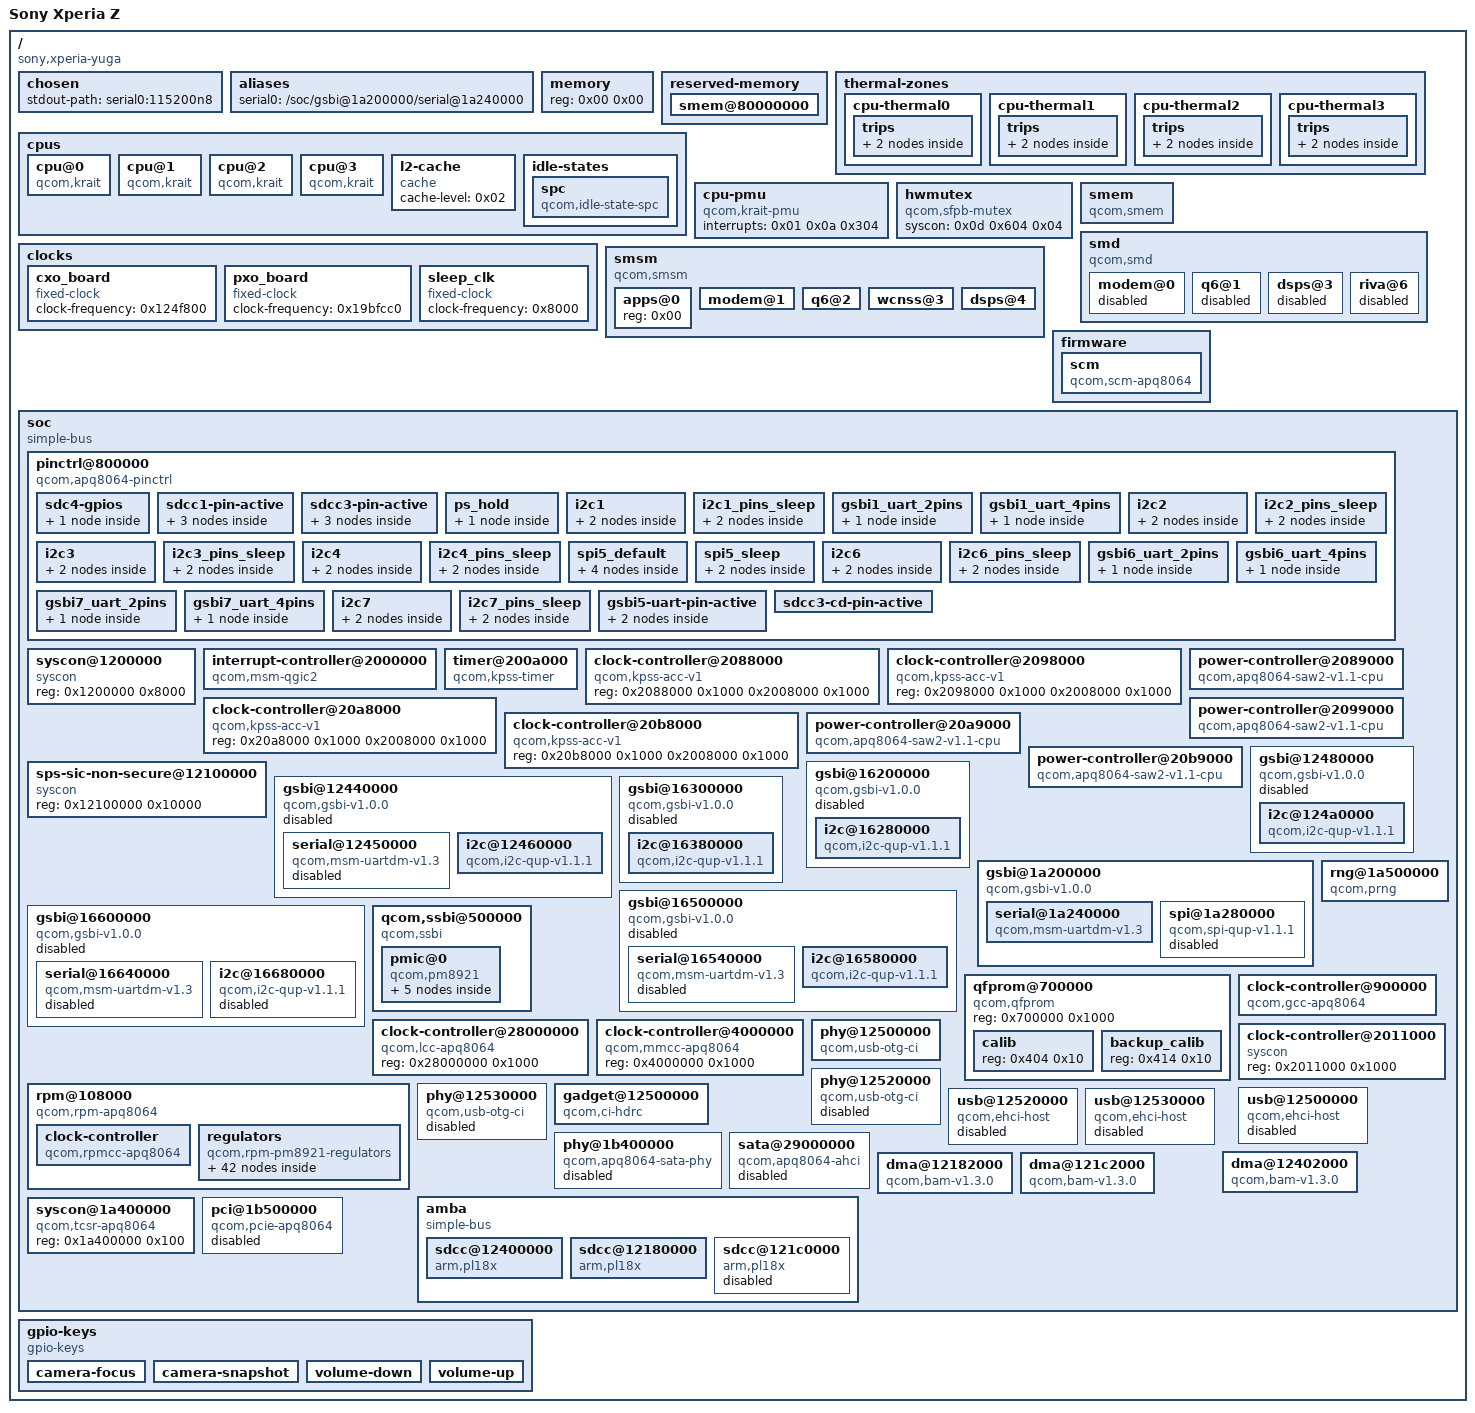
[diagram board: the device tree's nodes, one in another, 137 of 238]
/dts-v1/;

/ {
	#address-cells = <0x01>;
	#size-cells = <0x01>;
	model = "Sony Xperia Z";
	compatible = "sony,xperia-yuga\0qcom,apq8064";
	interrupt-parent = <0x01>;

	chosen {
		stdout-path = "serial0:115200n8";
	};

	aliases {
		serial0 = "/soc/gsbi@1a200000/serial@1a240000";
	};

	memory {
		device_type = "memory";
		reg = <0x00 0x00>;
	};

	reserved-memory {
		#address-cells = <0x01>;
		#size-cells = <0x01>;
		ranges;

		smem@80000000 {
			reg = <0x80000000 0x200000>;
			no-map;
			phandle = <0x0e>;
		};
	};

	cpus {
		#address-cells = <0x01>;
		#size-cells = <0x00>;

		cpu@0 {
			compatible = "qcom,krait";
			enable-method = "qcom,kpss-acc-v1";
			device_type = "cpu";
			reg = <0x00>;
			next-level-cache = <0x02>;
			qcom,acc = <0x03>;
			qcom,saw = <0x04>;
			cpu-idle-states = <0x05>;
		};

		cpu@1 {
			compatible = "qcom,krait";
			enable-method = "qcom,kpss-acc-v1";
			device_type = "cpu";
			reg = <0x01>;
			next-level-cache = <0x02>;
			qcom,acc = <0x06>;
			qcom,saw = <0x07>;
			cpu-idle-states = <0x05>;
		};

		cpu@2 {
			compatible = "qcom,krait";
			enable-method = "qcom,kpss-acc-v1";
			device_type = "cpu";
			reg = <0x02>;
			next-level-cache = <0x02>;
			qcom,acc = <0x08>;
			qcom,saw = <0x09>;
			cpu-idle-states = <0x05>;
		};

		cpu@3 {
			compatible = "qcom,krait";
			enable-method = "qcom,kpss-acc-v1";
			device_type = "cpu";
			reg = <0x03>;
			next-level-cache = <0x02>;
			qcom,acc = <0x0a>;
			qcom,saw = <0x0b>;
			cpu-idle-states = <0x05>;
		};

		l2-cache {
			compatible = "cache";
			cache-level = <0x02>;
			phandle = <0x02>;
		};

		idle-states {

			spc {
				compatible = "qcom,idle-state-spc\0arm,idle-state";
				entry-latency-us = <0x190>;
				exit-latency-us = <0x384>;
				min-residency-us = <0xbb8>;
				phandle = <0x05>;
			};
		};
	};

	thermal-zones {

		cpu-thermal0 {
			polling-delay-passive = <0xfa>;
			polling-delay = <0x3e8>;
			thermal-sensors = <0x0c 0x07>;
			coefficients = <0x4af 0x00>;

			trips {

				trip0 {
					temperature = <0x124f8>;
					hysteresis = <0x7d0>;
					type = "passive";
					phandle = <0x3c>;
				};

				trip1 {
					temperature = <0x1adb0>;
					hysteresis = <0x7d0>;
					type = "critical";
					phandle = <0x3d>;
				};
			};
		};

		cpu-thermal1 {
			polling-delay-passive = <0xfa>;
			polling-delay = <0x3e8>;
			thermal-sensors = <0x0c 0x08>;
			coefficients = <0x46c 0x00>;

			trips {

				trip0 {
					temperature = <0x124f8>;
					hysteresis = <0x7d0>;
					type = "passive";
					phandle = <0x3e>;
				};

				trip1 {
					temperature = <0x1adb0>;
					hysteresis = <0x7d0>;
					type = "critical";
					phandle = <0x3f>;
				};
			};
		};

		cpu-thermal2 {
			polling-delay-passive = <0xfa>;
			polling-delay = <0x3e8>;
			thermal-sensors = <0x0c 0x09>;
			coefficients = <0x4af 0x00>;

			trips {

				trip0 {
					temperature = <0x124f8>;
					hysteresis = <0x7d0>;
					type = "passive";
					phandle = <0x40>;
				};

				trip1 {
					temperature = <0x1adb0>;
					hysteresis = <0x7d0>;
					type = "critical";
					phandle = <0x41>;
				};
			};
		};

		cpu-thermal3 {
			polling-delay-passive = <0xfa>;
			polling-delay = <0x3e8>;
			thermal-sensors = <0x0c 0x0a>;
			coefficients = <0x46c 0x00>;

			trips {

				trip0 {
					temperature = <0x124f8>;
					hysteresis = <0x7d0>;
					type = "passive";
					phandle = <0x42>;
				};

				trip1 {
					temperature = <0x1adb0>;
					hysteresis = <0x7d0>;
					type = "critical";
					phandle = <0x43>;
				};
			};
		};
	};

	cpu-pmu {
		compatible = "qcom,krait-pmu";
		interrupts = <0x01 0x0a 0x304>;
	};

	clocks {

		cxo_board {
			compatible = "fixed-clock";
			#clock-cells = <0x00>;
			clock-frequency = <0x124f800>;
		};

		pxo_board {
			compatible = "fixed-clock";
			#clock-cells = <0x00>;
			clock-frequency = <0x19bfcc0>;
		};

		sleep_clk {
			compatible = "fixed-clock";
			#clock-cells = <0x00>;
			clock-frequency = <0x8000>;
		};
	};

	hwmutex {
		compatible = "qcom,sfpb-mutex";
		syscon = <0x0d 0x604 0x04>;
		#hwlock-cells = <0x01>;
		phandle = <0x0f>;
	};

	smem {
		compatible = "qcom,smem";
		memory-region = <0x0e>;
		hwlocks = <0x0f 0x03>;
	};

	smd {
		compatible = "qcom,smd";

		modem@0 {
			interrupts = <0x00 0x25 0x01>;
			qcom,ipc = <0x10 0x08 0x03>;
			qcom,smd-edge = <0x00>;
			status = "disabled";
		};

		q6@1 {
			interrupts = <0x00 0x5a 0x01>;
			qcom,ipc = <0x10 0x08 0x0f>;
			qcom,smd-edge = <0x01>;
			status = "disabled";
		};

		dsps@3 {
			interrupts = <0x00 0x8a 0x01>;
			qcom,ipc = <0x11 0x4080 0x00>;
			qcom,smd-edge = <0x03>;
			status = "disabled";
		};

		riva@6 {
			interrupts = <0x00 0xc6 0x01>;
			qcom,ipc = <0x10 0x08 0x19>;
			qcom,smd-edge = <0x06>;
			status = "disabled";
		};
	};

	smsm {
		compatible = "qcom,smsm";
		#address-cells = <0x01>;
		#size-cells = <0x00>;
		qcom,ipc-1 = <0x10 0x08 0x04>;
		qcom,ipc-2 = <0x10 0x08 0x0e>;
		qcom,ipc-3 = <0x10 0x08 0x17>;
		qcom,ipc-4 = <0x11 0x4094 0x00>;

		apps@0 {
			reg = <0x00>;
			#qcom,smem-state-cells = <0x01>;
			phandle = <0x44>;
		};

		modem@1 {
			reg = <0x01>;
			interrupts = <0x00 0x26 0x01>;
			interrupt-controller;
			#interrupt-cells = <0x02>;
			phandle = <0x45>;
		};

		q6@2 {
			reg = <0x02>;
			interrupts = <0x00 0x59 0x01>;
			interrupt-controller;
			#interrupt-cells = <0x02>;
			phandle = <0x46>;
		};

		wcnss@3 {
			reg = <0x03>;
			interrupts = <0x00 0xcc 0x01>;
			interrupt-controller;
			#interrupt-cells = <0x02>;
			phandle = <0x47>;
		};

		dsps@4 {
			reg = <0x04>;
			interrupts = <0x00 0x89 0x01>;
			interrupt-controller;
			#interrupt-cells = <0x02>;
			phandle = <0x48>;
		};
	};

	firmware {

		scm {
			compatible = "qcom,scm-apq8064";
		};
	};

	soc {
		#address-cells = <0x01>;
		#size-cells = <0x01>;
		ranges;
		compatible = "simple-bus";
		phandle = <0x49>;

		pinctrl@800000 {
			compatible = "qcom,apq8064-pinctrl";
			reg = <0x800000 0x4000>;
			gpio-controller;
			#gpio-cells = <0x02>;
			interrupt-controller;
			#interrupt-cells = <0x02>;
			interrupts = <0x00 0x10 0x04>;
			pinctrl-names = "default";
			pinctrl-0 = <0x12>;
			phandle = <0x23>;

			sdc4-gpios {
				phandle = <0x39>;

				pios {
					pins = "gpio63\0gpio64\0gpio65\0gpio66\0gpio67\0gpio68";
					function = "sdc4";
				};
			};

			sdcc1-pin-active {
				phandle = <0x32>;

				clk {
					pins = "sdc1_clk";
					drive-strengh = <0x10>;
					bias-disable;
				};

				cmd {
					pins = "sdc1_cmd";
					drive-strengh = <0x0a>;
					bias-pull-up;
				};

				data {
					pins = "sdc1_data";
					drive-strengh = <0x0a>;
					bias-pull-up;
				};
			};

			sdcc3-pin-active {
				phandle = <0x36>;

				clk {
					pins = "sdc3_clk";
					drive-strengh = <0x08>;
					bias-disable;
				};

				cmd {
					pins = "sdc3_cmd";
					drive-strengh = <0x08>;
					bias-pull-up;
				};

				data {
					pins = "sdc3_data";
					drive-strengh = <0x08>;
					bias-pull-up;
				};
			};

			ps_hold {
				phandle = <0x12>;

				mux {
					pins = "gpio78";
					function = "ps_hold";
				};
			};

			i2c1 {
				phandle = <0x14>;

				mux {
					pins = "gpio20\0gpio21";
					function = "gsbi1";
				};

				pinconf {
					pins = "gpio20\0gpio21";
					drive-strength = <0x10>;
					bias-disable;
				};
			};

			i2c1_pins_sleep {
				phandle = <0x15>;

				mux {
					pins = "gpio20\0gpio21";
					function = "gpio";
				};

				pinconf {
					pins = "gpio20\0gpio21";
					drive-strength = <0x02>;
					bias-disable = <0x00>;
				};
			};

			gsbi1_uart_2pins {
				phandle = <0x4a>;

				mux {
					pins = "gpio18\0gpio19";
					function = "gsbi1";
				};
			};

			gsbi1_uart_4pins {
				phandle = <0x4b>;

				mux {
					pins = "gpio18\0gpio19\0gpio20\0gpio21";
					function = "gsbi1";
				};
			};

			i2c2 {
				phandle = <0x16>;

				mux {
					pins = "gpio24\0gpio25";
					function = "gsbi2";
				};

				pinconf {
					pins = "gpio24\0gpio25";
					drive-strength = <0x10>;
					bias-disable;
				};
			};

			i2c2_pins_sleep {
				phandle = <0x17>;

				mux {
					pins = "gpio24\0gpio25";
					function = "gpio";
				};

				pinconf {
					pins = "gpio24\0gpio25";
					drive-strength = <0x02>;
					bias-disable = <0x00>;
				};
			};

			i2c3 {
				phandle = <0x18>;

				mux {
					pins = "gpio8\0gpio9";
					function = "gsbi3";
				};

				pinconf {
					pins = "gpio8\0gpio9";
					drive-strength = <0x10>;
					bias-disable;
				};
			};

			i2c3_pins_sleep {
				phandle = <0x19>;

				mux {
					pins = "gpio8\0gpio9";
					function = "gpio";
				};

				pinconf {
					pins = "gpio8\0gpio9";
					drive-strength = <0x02>;
					bias-disable = <0x00>;
				};
			};

			i2c4 {
				phandle = <0x1a>;

				mux {
					pins = "gpio12\0gpio13";
					function = "gsbi4";
				};

				pinconf {
					pins = "gpio12\0gpio13";
					drive-strength = <0x10>;
					bias-disable;
				};
			};

			i2c4_pins_sleep {
				phandle = <0x1b>;

				mux {
					pins = "gpio12\0gpio13";
					function = "gpio";
				};

				pinconf {
					pins = "gpio12\0gpio13";
					drive-strength = <0x02>;
					bias-disable = <0x00>;
				};
			};

			spi5_default {
				phandle = <0x1d>;

				pinmux {
					pins = "gpio51\0gpio52\0gpio54";
					function = "gsbi5";
				};

				pinmux_cs {
					function = "gpio";
					pins = "gpio53";
				};

				pinconf {
					pins = "gpio51\0gpio52\0gpio54";
					drive-strength = <0x10>;
					bias-disable;
				};

				pinconf_cs {
					pins = "gpio53";
					drive-strength = <0x10>;
					bias-disable;
					output-high;
				};
			};

			spi5_sleep {
				phandle = <0x1e>;

				pinmux {
					function = "gpio";
					pins = "gpio51\0gpio52\0gpio53\0gpio54";
				};

				pinconf {
					pins = "gpio51\0gpio52\0gpio53\0gpio54";
					drive-strength = <0x02>;
					bias-pull-down;
				};
			};

			i2c6 {
				phandle = <0x1f>;

				mux {
					pins = "gpio16\0gpio17";
					function = "gsbi6";
				};

				pinconf {
					pins = "gpio16\0gpio17";
					drive-strength = <0x10>;
					bias-disable;
				};
			};

			i2c6_pins_sleep {
				phandle = <0x20>;

				mux {
					pins = "gpio16\0gpio17";
					function = "gpio";
				};

				pinconf {
					pins = "gpio16\0gpio17";
					drive-strength = <0x02>;
					bias-disable = <0x00>;
				};
			};

			gsbi6_uart_2pins {
				phandle = <0x4c>;

				mux {
					pins = "gpio14\0gpio15";
					function = "gsbi6";
				};
			};

			gsbi6_uart_4pins {
				phandle = <0x4d>;

				mux {
					pins = "gpio14\0gpio15\0gpio16\0gpio17";
					function = "gsbi6";
				};
			};

			gsbi7_uart_2pins {
				phandle = <0x4e>;

				mux {
					pins = "gpio82\0gpio83";
					function = "gsbi7";
				};
			};

			gsbi7_uart_4pins {
				phandle = <0x4f>;

				mux {
					pins = "gpio82\0gpio83\0gpio84\0gpio85";
					function = "gsbi7";
				};
			};

			i2c7 {
				phandle = <0x21>;

				mux {
					pins = "gpio84\0gpio85";
					function = "gsbi7";
				};

				pinconf {
					pins = "gpio84\0gpio85";
					drive-strength = <0x10>;
					bias-disable;
				};
			};

			i2c7_pins_sleep {
				phandle = <0x22>;

				mux {
					pins = "gpio84\0gpio85";
					function = "gpio";
				};

				pinconf {
					pins = "gpio84\0gpio85";
					drive-strength = <0x02>;
					bias-disable = <0x00>;
				};
			};

			gsbi5-uart-pin-active {
				phandle = <0x1c>;

				rx {
					pins = "gpio52";
					function = "gsbi5";
					drive-strength = <0x02>;
					bias-pull-up;
				};

				tx {
					pins = "gpio51";
					function = "gsbi5";
					drive-strength = <0x04>;
					bias-disable;
				};
			};

			sdcc3-cd-pin-active {
				pins = "gpio26";
				function = "gpio";
				drive-strength = <0x02>;
				bias-disable;
				phandle = <0x37>;
			};
		};

		syscon@1200000 {
			compatible = "syscon";
			reg = <0x1200000 0x8000>;
			phandle = <0x0d>;
		};

		interrupt-controller@2000000 {
			compatible = "qcom,msm-qgic2";
			interrupt-controller;
			#interrupt-cells = <0x03>;
			reg = <0x2000000 0x1000 0x2002000 0x1000>;
			phandle = <0x01>;
		};

		timer@200a000 {
			compatible = "qcom,kpss-timer\0qcom,kpss-wdt-apq8064\0qcom,msm-timer";
			interrupts = <0x01 0x01 0x301 0x01 0x02 0x301 0x01 0x03 0x301>;
			reg = <0x200a000 0x100>;
			clock-frequency = <0x19bfcc0 0x8000>;
			cpu-offset = <0x80000>;
		};

		clock-controller@2088000 {
			compatible = "qcom,kpss-acc-v1";
			reg = <0x2088000 0x1000 0x2008000 0x1000>;
			phandle = <0x03>;
		};

		clock-controller@2098000 {
			compatible = "qcom,kpss-acc-v1";
			reg = <0x2098000 0x1000 0x2008000 0x1000>;
			phandle = <0x06>;
		};

		clock-controller@20a8000 {
			compatible = "qcom,kpss-acc-v1";
			reg = <0x20a8000 0x1000 0x2008000 0x1000>;
			phandle = <0x08>;
		};

		clock-controller@20b8000 {
			compatible = "qcom,kpss-acc-v1";
			reg = <0x20b8000 0x1000 0x2008000 0x1000>;
			phandle = <0x0a>;
		};

		power-controller@2089000 {
			compatible = "qcom,apq8064-saw2-v1.1-cpu\0qcom,saw2";
			reg = <0x2089000 0x1000 0x2009000 0x1000>;
			regulator;
			phandle = <0x04>;
		};

		power-controller@2099000 {
			compatible = "qcom,apq8064-saw2-v1.1-cpu\0qcom,saw2";
			reg = <0x2099000 0x1000 0x2009000 0x1000>;
			regulator;
			phandle = <0x07>;
		};

		power-controller@20a9000 {
			compatible = "qcom,apq8064-saw2-v1.1-cpu\0qcom,saw2";
			reg = <0x20a9000 0x1000 0x2009000 0x1000>;
			regulator;
			phandle = <0x09>;
		};

		power-controller@20b9000 {
			compatible = "qcom,apq8064-saw2-v1.1-cpu\0qcom,saw2";
			reg = <0x20b9000 0x1000 0x2009000 0x1000>;
			regulator;
			phandle = <0x0b>;
		};

		sps-sic-non-secure@12100000 {
			compatible = "syscon";
			reg = <0x12100000 0x10000>;
			phandle = <0x11>;
		};

		gsbi@12440000 {
			status = "disabled";
			compatible = "qcom,gsbi-v1.0.0";
			cell-index = <0x01>;
			reg = <0x12440000 0x100>;
			clocks = <0x0c 0x93>;
			clock-names = "iface";
			#address-cells = <0x01>;
			#size-cells = <0x01>;
			ranges;
			syscon-tcsr = <0x13>;
			phandle = <0x50>;

			serial@12450000 {
				compatible = "qcom,msm-uartdm-v1.3\0qcom,msm-uartdm";
				reg = <0x12450000 0x100 0x12400000 0x03>;
				interrupts = <0x00 0xc1 0x00>;
				clocks = <0x0c 0xa0 0x0c 0x93>;
				clock-names = "core\0iface";
				status = "disabled";
				phandle = <0x51>;
			};

			i2c@12460000 {
				compatible = "qcom,i2c-qup-v1.1.1";
				pinctrl-0 = <0x14>;
				pinctrl-1 = <0x15>;
				pinctrl-names = "default\0sleep";
				reg = <0x12460000 0x1000>;
				interrupts = <0x00 0xc2 0x00>;
				clocks = <0x0c 0xb8 0x0c 0x93>;
				clock-names = "core\0iface";
				#address-cells = <0x01>;
				#size-cells = <0x00>;
				phandle = <0x52>;
			};
		};

		gsbi@12480000 {
			status = "disabled";
			compatible = "qcom,gsbi-v1.0.0";
			cell-index = <0x02>;
			reg = <0x12480000 0x100>;
			clocks = <0x0c 0x94>;
			clock-names = "iface";
			#address-cells = <0x01>;
			#size-cells = <0x01>;
			ranges;
			syscon-tcsr = <0x13>;
			phandle = <0x53>;

			i2c@124a0000 {
				compatible = "qcom,i2c-qup-v1.1.1";
				reg = <0x124a0000 0x1000>;
				pinctrl-0 = <0x16>;
				pinctrl-1 = <0x17>;
				pinctrl-names = "default\0sleep";
				interrupts = <0x00 0xc4 0x00>;
				clocks = <0x0c 0xba 0x0c 0x94>;
				clock-names = "core\0iface";
				#address-cells = <0x01>;
				#size-cells = <0x00>;
				phandle = <0x54>;
			};
		};

		gsbi@16200000 {
			status = "disabled";
			compatible = "qcom,gsbi-v1.0.0";
			cell-index = <0x03>;
			reg = <0x16200000 0x100>;
			clocks = <0x0c 0x95>;
			clock-names = "iface";
			#address-cells = <0x01>;
			#size-cells = <0x01>;
			ranges;
			phandle = <0x55>;

			i2c@16280000 {
				compatible = "qcom,i2c-qup-v1.1.1";
				pinctrl-0 = <0x18>;
				pinctrl-1 = <0x19>;
				pinctrl-names = "default\0sleep";
				reg = <0x16280000 0x1000>;
				interrupts = <0x00 0x97 0x00>;
				clocks = <0x0c 0xbc 0x0c 0x95>;
				clock-names = "core\0iface";
				#address-cells = <0x01>;
				#size-cells = <0x00>;
				phandle = <0x56>;
			};
		};

		gsbi@16300000 {
			status = "disabled";
			compatible = "qcom,gsbi-v1.0.0";
			cell-index = <0x04>;
			reg = <0x16300000 0x03>;
			clocks = <0x0c 0x96>;
			clock-names = "iface";
			#address-cells = <0x01>;
			#size-cells = <0x01>;
			ranges;
			phandle = <0x57>;

			i2c@16380000 {
				compatible = "qcom,i2c-qup-v1.1.1";
				pinctrl-0 = <0x1a>;
				pinctrl-1 = <0x1b>;
				pinctrl-names = "default\0sleep";
				reg = <0x16380000 0x1000>;
				interrupts = <0x00 0x99 0x00>;
				clocks = <0x0c 0xbe 0x0c 0x96>;
				clock-names = "core\0iface";
				phandle = <0x58>;
			};
		};

		gsbi@1a200000 {
			status = "ok";
			compatible = "qcom,gsbi-v1.0.0";
			cell-index = <0x05>;
			reg = <0x1a200000 0x03>;
			clocks = <0x0c 0x97>;
			clock-names = "iface";
			#address-cells = <0x01>;
			#size-cells = <0x01>;
			ranges;
			qcom,mode = <0x06>;
			phandle = <0x59>;

			serial@1a240000 {
				compatible = "qcom,msm-uartdm-v1.3\0qcom,msm-uartdm";
				reg = <0x1a240000 0x100 0x1a200000 0x03>;
				interrupts = <0x00 0x9a 0x00>;
				clocks = <0x0c 0xa8 0x0c 0x97>;
				clock-names = "core\0iface";
				status = "ok";
				pinctrl-names = "default";
				pinctrl-0 = <0x1c>;
				phandle = <0x5a>;
			};

			spi@1a280000 {
				compatible = "qcom,spi-qup-v1.1.1";
				reg = <0x1a280000 0x1000>;
				interrupts = <0x00 0x9b 0x00>;
				pinctrl-0 = <0x1d>;
				pinctrl-1 = <0x1e>;
				pinctrl-names = "default\0sleep";
				clocks = <0x0c 0xc0 0x0c 0x97>;
				clock-names = "core\0iface";
				status = "disabled";
				#address-cells = <0x01>;
				#size-cells = <0x00>;
				phandle = <0x5b>;
			};
		};

		gsbi@16500000 {
			status = "disabled";
			compatible = "qcom,gsbi-v1.0.0";
			cell-index = <0x06>;
			reg = <0x16500000 0x03>;
			clocks = <0x0c 0x98>;
			clock-names = "iface";
			#address-cells = <0x01>;
			#size-cells = <0x01>;
			ranges;
			phandle = <0x5c>;

			serial@16540000 {
				compatible = "qcom,msm-uartdm-v1.3\0qcom,msm-uartdm";
				reg = <0x16540000 0x100 0x16500000 0x03>;
				interrupts = <0x00 0x9c 0x00>;
				clocks = <0x0c 0xaa 0x0c 0x98>;
				clock-names = "core\0iface";
				status = "disabled";
				phandle = <0x5d>;
			};

			i2c@16580000 {
				compatible = "qcom,i2c-qup-v1.1.1";
				pinctrl-0 = <0x1f>;
				pinctrl-1 = <0x20>;
				pinctrl-names = "default\0sleep";
				reg = <0x16580000 0x1000>;
				interrupts = <0x00 0x9d 0x00>;
				clocks = <0x0c 0xc2 0x0c 0x98>;
				clock-names = "core\0iface";
				phandle = <0x5e>;
			};
		};

		gsbi@16600000 {
			status = "disabled";
			compatible = "qcom,gsbi-v1.0.0";
			cell-index = <0x07>;
			reg = <0x16600000 0x100>;
			clocks = <0x0c 0x99>;
			clock-names = "iface";
			#address-cells = <0x01>;
			#size-cells = <0x01>;
			ranges;
			syscon-tcsr = <0x13>;
			phandle = <0x5f>;

			serial@16640000 {
				compatible = "qcom,msm-uartdm-v1.3\0qcom,msm-uartdm";
				reg = <0x16640000 0x1000 0x16600000 0x1000>;
				interrupts = <0x00 0x9e 0x00>;
				clocks = <0x0c 0xac 0x0c 0x99>;
				clock-names = "core\0iface";
				status = "disabled";
				phandle = <0x60>;
			};

			i2c@16680000 {
				compatible = "qcom,i2c-qup-v1.1.1";
				pinctrl-0 = <0x21>;
				pinctrl-1 = <0x22>;
				pinctrl-names = "default\0sleep";
				reg = <0x16680000 0x1000>;
				interrupts = <0x00 0x9f 0x00>;
				clocks = <0x0c 0xc4 0x0c 0x99>;
				clock-names = "core\0iface";
				status = "disabled";
				phandle = <0x61>;
			};
		};

		rng@1a500000 {
			compatible = "qcom,prng";
			reg = <0x1a500000 0x200>;
			clocks = <0x0c 0x108>;
			clock-names = "core";
		};

		qcom,ssbi@500000 {
			compatible = "qcom,ssbi";
			reg = <0x500000 0x1000>;
			qcom,controller-type = "pmic-arbiter";

			pmic@0 {
				compatible = "qcom,pm8921";
				interrupt-parent = <0x23>;
				interrupts = <0x4a 0x08>;
				#interrupt-cells = <0x02>;
				interrupt-controller;
				#address-cells = <0x01>;
				#size-cells = <0x00>;
				phandle = <0x24>;

				gpio@150 {
					compatible = "qcom,pm8921-gpio\0qcom,ssbi-gpio";
					reg = <0x150>;
					interrupts = <0xc0 0x00 0xc1 0x00 0xc2 0x00 0xc3 0x00 0xc4 0x00 0xc5 0x00 0xc6 0x00 0xc7 0x00 0xc8 0x00 0xc9 0x00 0xca 0x00 0xcb 0x00 0xcc 0x00 0xcd 0x00 0xce 0x00 0xcf 0x00 0xd0 0x00 0xd1 0x00 0xd2 0x00 0xd3 0x00 0xd4 0x00 0xd5 0x00 0xd6 0x00 0xd7 0x00 0xd8 0x00 0xd9 0x00 0xda 0x00 0xdb 0x00 0xdc 0x00 0xdd 0x00 0xde 0x00 0xdf 0x00 0xe0 0x00 0xe1 0x00 0xe2 0x00 0xe3 0x00 0xe4 0x00 0xe5 0x00 0xe6 0x00 0xe7 0x00 0xe8 0x00 0xe9 0x00 0xea 0x00 0xeb 0x00>;
					gpio-controller;
					#gpio-cells = <0x02>;
					phandle = <0x3b>;

					gpio-keys-pin-active {
						pins = "gpio3\0gpio4\0gpio29\0gpio35";
						function = "normal";
						bias-pull-up;
						drive-push-pull;
						input-enable;
						power-source = <0x02>;
						qcom,drive-strength = <0x00>;
						qcom,pull-up-strength = <0x00>;
						phandle = <0x3a>;
					};
				};

				mpps@50 {
					compatible = "qcom,pm8921-mpp\0qcom,ssbi-mpp";
					reg = <0x50>;
					gpio-controller;
					#gpio-cells = <0x02>;
					interrupts = <0x80 0x00 0x81 0x00 0x82 0x00 0x83 0x00 0x84 0x00 0x85 0x00 0x86 0x00 0x87 0x00 0x88 0x00 0x89 0x00 0x8a 0x00 0x8b 0x00>;
					phandle = <0x62>;
				};

				rtc@11d {
					compatible = "qcom,pm8921-rtc";
					interrupt-parent = <0x24>;
					interrupts = <0x27 0x01>;
					reg = <0x11d>;
					allow-set-time;
				};

				pwrkey@1c {
					compatible = "qcom,pm8921-pwrkey";
					reg = <0x1c>;
					interrupt-parent = <0x24>;
					interrupts = <0x32 0x01 0x33 0x01>;
					debounce = <0x3d09>;
					pull-up;
				};
			};
		};

		qfprom@700000 {
			compatible = "qcom,qfprom";
			reg = <0x700000 0x1000>;
			#address-cells = <0x01>;
			#size-cells = <0x01>;
			ranges;
			phandle = <0x63>;

			calib {
				reg = <0x404 0x10>;
				phandle = <0x25>;
			};

			backup_calib {
				reg = <0x414 0x10>;
				phandle = <0x26>;
			};
		};

		clock-controller@900000 {
			compatible = "qcom,gcc-apq8064";
			reg = <0x900000 0x4000>;
			nvmem-cells = <0x25 0x26>;
			nvmem-cell-names = "calib\0calib_backup";
			#clock-cells = <0x01>;
			#reset-cells = <0x01>;
			#thermal-sensor-cells = <0x01>;
			phandle = <0x0c>;
		};

		clock-controller@28000000 {
			compatible = "qcom,lcc-apq8064";
			reg = <0x28000000 0x1000>;
			#clock-cells = <0x01>;
			#reset-cells = <0x01>;
			phandle = <0x64>;
		};

		clock-controller@4000000 {
			compatible = "qcom,mmcc-apq8064";
			reg = <0x4000000 0x1000>;
			#clock-cells = <0x01>;
			#reset-cells = <0x01>;
			phandle = <0x65>;
		};

		clock-controller@2011000 {
			compatible = "syscon";
			reg = <0x2011000 0x1000>;
			phandle = <0x10>;
		};

		rpm@108000 {
			compatible = "qcom,rpm-apq8064";
			reg = <0x108000 0x1000>;
			qcom,ipc = <0x10 0x08 0x02>;
			interrupts = <0x00 0x13 0x01 0x00 0x15 0x01 0x00 0x16 0x01>;
			interrupt-names = "ack\0err\0wakeup";

			clock-controller {
				compatible = "qcom,rpmcc-apq8064\0qcom,rpmcc";
				#clock-cells = <0x01>;
				phandle = <0x66>;
			};

			regulators {
				compatible = "qcom,rpm-pm8921-regulators";
				vin_l1_l2_l12_l18-supply = <0x27>;
				vin_lvs_1_3_6-supply = <0x27>;
				vin_lvs_4_5_7-supply = <0x27>;
				vin_ncp-supply = <0x28>;
				vin_lvs2-supply = <0x27>;
				vin_l24-supply = <0x29>;
				vin_l25-supply = <0x29>;
				vin_l27-supply = <0x2a>;
				vin_l28-supply = <0x2a>;

				s1 {
					regulator-always-on;
					regulator-min-microvolt = <0x12b128>;
					regulator-max-microvolt = <0x12b128>;
					qcom,switch-mode-frequency = <0x30d400>;
					bias-pull-down;
					phandle = <0x29>;
				};

				s2 {
					regulator-min-microvolt = <0x13d620>;
					regulator-max-microvolt = <0x13d620>;
					qcom,switch-mode-frequency = <0x186a00>;
					bias-pull-down;
					phandle = <0x67>;
				};

				s3 {
					regulator-min-microvolt = <0x7a120>;
					regulator-max-microvolt = <0x118c30>;
					qcom,switch-mode-frequency = <0x493e00>;
					bias-pull-down;
					phandle = <0x2b>;
				};

				s4 {
					regulator-always-on;
					regulator-min-microvolt = <0x1b7740>;
					regulator-max-microvolt = <0x1b7740>;
					qcom,switch-mode-frequency = <0x186a00>;
					bias-pull-down;
					qcom,force-mode = <0x03>;
					phandle = <0x27>;
				};

				s7 {
					regulator-min-microvolt = <0x13d620>;
					regulator-max-microvolt = <0x13d620>;
					qcom,switch-mode-frequency = <0x30d400>;
					phandle = <0x2a>;
				};

				s8 {
					regulator-min-microvolt = <0x2191c0>;
					regulator-max-microvolt = <0x2191c0>;
					qcom,switch-mode-frequency = <0x186a00>;
					phandle = <0x68>;
				};

				l1 {
					regulator-always-on;
					regulator-min-microvolt = <0x10c8e0>;
					regulator-max-microvolt = <0x10c8e0>;
					bias-pull-down;
					phandle = <0x69>;
				};

				l2 {
					regulator-min-microvolt = <0x124f80>;
					regulator-max-microvolt = <0x124f80>;
					bias-pull-down;
					phandle = <0x6a>;
				};

				l3 {
					regulator-min-microvolt = <0x2eebb8>;
					regulator-max-microvolt = <0x2eebb8>;
					bias-pull-down;
					phandle = <0x2c>;
				};

				l4 {
					regulator-always-on;
					regulator-min-microvolt = <0x1b7740>;
					regulator-max-microvolt = <0x1b7740>;
					bias-pull-down;
					phandle = <0x2d>;
				};

				l5 {
					regulator-min-microvolt = <0x2d0370>;
					regulator-max-microvolt = <0x2d0370>;
					bias-pull-down;
					phandle = <0x34>;
				};

				l6 {
					regulator-min-microvolt = <0x2d0370>;
					regulator-max-microvolt = <0x2d0370>;
					bias-pull-down;
					phandle = <0x28>;
				};

				l7 {
					regulator-min-microvolt = <0x1c3a90>;
					regulator-max-microvolt = <0x2d0370>;
					bias-pull-down;
					phandle = <0x6b>;
				};

				l8 {
					regulator-min-microvolt = <0x2ab980>;
					regulator-max-microvolt = <0x2ab980>;
					bias-pull-down;
					phandle = <0x6c>;
				};

				l9 {
					regulator-min-microvolt = <0x2dc6c0>;
					regulator-max-microvolt = <0x2dc6c0>;
					bias-pull-down;
					phandle = <0x6d>;
				};

				l10 {
					regulator-min-microvolt = <0x2c4020>;
					regulator-max-microvolt = <0x2c4020>;
					bias-pull-down;
					phandle = <0x6e>;
				};

				l11 {
					regulator-min-microvolt = <0x2dc6c0>;
					regulator-max-microvolt = <0x2dc6c0>;
					bias-pull-down;
					phandle = <0x6f>;
				};

				l12 {
					regulator-min-microvolt = <0x124f80>;
					regulator-max-microvolt = <0x124f80>;
					bias-pull-down;
					phandle = <0x70>;
				};

				l14 {
					regulator-min-microvolt = <0x1b7740>;
					regulator-max-microvolt = <0x1b7740>;
					bias-pull-down;
					phandle = <0x71>;
				};

				l15 {
					regulator-min-microvolt = <0x1b7740>;
					regulator-max-microvolt = <0x2d0370>;
					bias-pull-down;
					phandle = <0x72>;
				};

				l16 {
					regulator-min-microvolt = <0x2ab980>;
					regulator-max-microvolt = <0x2ab980>;
					bias-pull-down;
					phandle = <0x73>;
				};

				l17 {
					regulator-min-microvolt = <0x1e8480>;
					regulator-max-microvolt = <0x1e8480>;
					bias-pull-down;
					phandle = <0x74>;
				};

				l18 {
					regulator-min-microvolt = <0x124f80>;
					regulator-max-microvolt = <0x124f80>;
					bias-pull-down;
					phandle = <0x75>;
				};

				l21 {
					regulator-min-microvolt = <0x100590>;
					regulator-max-microvolt = <0x100590>;
					bias-pull-down;
					phandle = <0x76>;
				};

				l22 {
					regulator-min-microvolt = <0x27ac40>;
					regulator-max-microvolt = <0x27ac40>;
					bias-pull-down;
					phandle = <0x77>;
				};

				l23 {
					regulator-min-microvolt = <0x1b7740>;
					regulator-max-microvolt = <0x1b7740>;
					bias-pull-down;
					phandle = <0x78>;
				};

				l24 {
					regulator-min-microvolt = <0xb71b0>;
					regulator-max-microvolt = <0x118c30>;
					bias-pull-down;
					phandle = <0x79>;
				};

				l25 {
					regulator-always-on;
					regulator-min-microvolt = <0x1312d0>;
					regulator-max-microvolt = <0x1312d0>;
					bias-pull-down;
					phandle = <0x7a>;
				};

				l26 {
					phandle = <0x7b>;
				};

				l27 {
					regulator-min-microvolt = <0x10c8e0>;
					regulator-max-microvolt = <0x10c8e0>;
					phandle = <0x7c>;
				};

				l28 {
					regulator-min-microvolt = <0x100590>;
					regulator-max-microvolt = <0x100590>;
					bias-pull-down;
					phandle = <0x7d>;
				};

				l29 {
					regulator-min-microvolt = <0x1e8480>;
					regulator-max-microvolt = <0x1e8480>;
					bias-pull-down;
					phandle = <0x7e>;
				};

				lvs1 {
					bias-pull-down;
					phandle = <0x7f>;
				};

				lvs2 {
					bias-pull-down;
					phandle = <0x80>;
				};

				lvs3 {
					bias-pull-down;
					phandle = <0x81>;
				};

				lvs4 {
					bias-pull-down;
					phandle = <0x82>;
				};

				lvs5 {
					bias-pull-down;
					phandle = <0x83>;
				};

				lvs6 {
					bias-pull-down;
					phandle = <0x84>;
				};

				lvs7 {
					bias-pull-down;
					phandle = <0x85>;
				};

				usb-switch {
					phandle = <0x86>;
				};

				hdmi-switch {
					bias-pull-down;
					phandle = <0x87>;
				};

				ncp {
					regulator-min-microvolt = <0x1b7740>;
					regulator-max-microvolt = <0x1b7740>;
					qcom,switch-mode-frequency = <0x186a00>;
					phandle = <0x88>;
				};
			};
		};

		phy@12500000 {
			compatible = "qcom,usb-otg-ci";
			reg = <0x12500000 0x400>;
			interrupts = <0x00 0x64 0x00>;
			status = "okay";
			clocks = <0x0c 0x80 0x0c 0x7e>;
			clock-names = "core\0iface";
			resets = <0x0c 0x40>;
			reset-names = "link";
			vddcx-supply = <0x2b>;
			v3p3-supply = <0x2c>;
			v1p8-supply = <0x2d>;
			phandle = <0x2e>;
		};

		phy@12520000 {
			compatible = "qcom,usb-otg-ci";
			reg = <0x12520000 0x400>;
			interrupts = <0x00 0xbc 0x00>;
			status = "disabled";
			dr_mode = "host";
			clocks = <0x0c 0x129 0x0c 0x127>;
			clock-names = "core\0iface";
			resets = <0x0c 0x64>;
			reset-names = "link";
			phandle = <0x2f>;
		};

		phy@12530000 {
			compatible = "qcom,usb-otg-ci";
			reg = <0x12530000 0x400>;
			interrupts = <0x00 0xd7 0x00>;
			status = "disabled";
			dr_mode = "host";
			clocks = <0x0c 0x12c 0x0c 0x12a>;
			clock-names = "core\0iface";
			resets = <0x0c 0x65>;
			reset-names = "link";
			phandle = <0x30>;
		};

		gadget@12500000 {
			compatible = "qcom,ci-hdrc";
			reg = <0x12500000 0x400>;
			status = "okay";
			dr_mode = "peripheral";
			interrupts = <0x00 0x64 0x00>;
			usb-phy = <0x2e>;
			phandle = <0x89>;
		};

		usb@12500000 {
			compatible = "qcom,ehci-host";
			reg = <0x12500000 0x400>;
			interrupts = <0x00 0x64 0x00>;
			status = "disabled";
			usb-phy = <0x2e>;
			phandle = <0x8a>;
		};

		usb@12520000 {
			compatible = "qcom,ehci-host";
			reg = <0x12520000 0x400>;
			interrupts = <0x00 0xbc 0x00>;
			status = "disabled";
			usb-phy = <0x2f>;
			phandle = <0x8b>;
		};

		usb@12530000 {
			compatible = "qcom,ehci-host";
			reg = <0x12530000 0x400>;
			interrupts = <0x00 0xd7 0x00>;
			status = "disabled";
			usb-phy = <0x30>;
			phandle = <0x8c>;
		};

		phy@1b400000 {
			compatible = "qcom,apq8064-sata-phy";
			status = "disabled";
			reg = <0x1b400000 0x200>;
			reg-names = "phy_mem";
			clocks = <0x0c 0x12d>;
			clock-names = "cfg";
			#phy-cells = <0x00>;
			phandle = <0x31>;
		};

		sata@29000000 {
			compatible = "qcom,apq8064-ahci\0generic-ahci";
			status = "disabled";
			reg = <0x29000000 0x180>;
			interrupts = <0x00 0xd1 0x00>;
			clocks = <0x0c 0x3b 0x0c 0xed 0x0c 0x12e 0x0c 0xef 0x0c 0xf0>;
			clock-names = "slave_iface\0iface\0bus\0rxoob\0core_pmalive";
			assigned-clocks = <0x0c 0xef 0x0c 0xf0>;
			assigned-clock-rates = <0x5f5e100 0x5f5e100>;
			phys = <0x31>;
			phy-names = "sata-phy";
			ports-implemented = <0x01>;
			phandle = <0x8d>;
		};

		dma@12402000 {
			compatible = "qcom,bam-v1.3.0";
			reg = <0x12402000 0x8000>;
			interrupts = <0x00 0x62 0x00>;
			clocks = <0x0c 0x6e>;
			clock-names = "bam_clk";
			#dma-cells = <0x01>;
			qcom,ee = <0x00>;
			phandle = <0x33>;
		};

		dma@12182000 {
			compatible = "qcom,bam-v1.3.0";
			reg = <0x12182000 0x8000>;
			interrupts = <0x00 0x60 0x00>;
			clocks = <0x0c 0x70>;
			clock-names = "bam_clk";
			#dma-cells = <0x01>;
			qcom,ee = <0x00>;
			phandle = <0x35>;
		};

		dma@121c2000 {
			compatible = "qcom,bam-v1.3.0";
			reg = <0x121c2000 0x8000>;
			interrupts = <0x00 0x5f 0x00>;
			clocks = <0x0c 0x71>;
			clock-names = "bam_clk";
			#dma-cells = <0x01>;
			qcom,ee = <0x00>;
			phandle = <0x38>;
		};

		amba {
			compatible = "simple-bus";
			#address-cells = <0x01>;
			#size-cells = <0x01>;
			ranges;

			sdcc@12400000 {
				status = "okay";
				compatible = "arm,pl18x\0arm,primecell";
				pinctrl-names = "default";
				pinctrl-0 = <0x32>;
				arm,primecell-periphid = <0x51180>;
				reg = <0x12400000 0x2000>;
				interrupts = <0x00 0x68 0x04>;
				interrupt-names = "cmd_irq";
				clocks = <0x0c 0x78 0x0c 0x6e>;
				clock-names = "mclk\0apb_pclk";
				bus-width = <0x08>;
				max-frequency = <0x5b8d800>;
				non-removable;
				cap-sd-highspeed;
				cap-mmc-highspeed;
				dmas = <0x33 0x02 0x33 0x01>;
				dma-names = "tx\0rx";
				vmmc-supply = <0x34>;
				vqmmc-supply = <0x27>;
				phandle = <0x8e>;
			};

			sdcc@12180000 {
				compatible = "arm,pl18x\0arm,primecell";
				arm,primecell-periphid = <0x51180>;
				status = "okay";
				reg = <0x12180000 0x2000>;
				interrupts = <0x00 0x66 0x04>;
				interrupt-names = "cmd_irq";
				clocks = <0x0c 0x7a 0x0c 0x70>;
				clock-names = "mclk\0apb_pclk";
				bus-width = <0x04>;
				cap-sd-highspeed;
				cap-mmc-highspeed;
				max-frequency = <0xb71b000>;
				no-1-8-v;
				dmas = <0x35 0x02 0x35 0x01>;
				dma-names = "tx\0rx";
				vmmc-supply = <0x28>;
				cd-gpios = <0x23 0x1a 0x01>;
				pinctrl-names = "default";
				pinctrl-0 = <0x36 0x37>;
				phandle = <0x8f>;
			};

			sdcc@121c0000 {
				compatible = "arm,pl18x\0arm,primecell";
				arm,primecell-periphid = <0x51180>;
				status = "disabled";
				reg = <0x121c0000 0x2000>;
				interrupts = <0x00 0x65 0x04>;
				interrupt-names = "cmd_irq";
				clocks = <0x0c 0x7b 0x0c 0x71>;
				clock-names = "mclk\0apb_pclk";
				bus-width = <0x04>;
				cap-sd-highspeed;
				cap-mmc-highspeed;
				max-frequency = <0x2dc6c00>;
				dmas = <0x38 0x02 0x38 0x01>;
				dma-names = "tx\0rx";
				pinctrl-names = "default";
				pinctrl-0 = <0x39>;
				phandle = <0x90>;
			};
		};

		syscon@1a400000 {
			compatible = "qcom,tcsr-apq8064\0syscon";
			reg = <0x1a400000 0x100>;
			phandle = <0x13>;
		};

		pci@1b500000 {
			compatible = "qcom,pcie-apq8064\0snps,dw-pcie";
			reg = <0x1b500000 0x1000 0x1b502000 0x80 0x1b600000 0x100 0xff00000 0x100000>;
			reg-names = "dbi\0elbi\0parf\0config";
			device_type = "pci";
			linux,pci-domain = <0x00>;
			bus-range = <0x00 0xff>;
			num-lanes = <0x01>;
			#address-cells = <0x03>;
			#size-cells = <0x02>;
			ranges = <0x81000000 0x00 0x00 0xfe00000 0x00 0x100000 0x82000000 0x00 0x00 0x8000000 0x00 0x7e00000>;
			interrupts = <0x00 0xee 0x00>;
			interrupt-names = "msi";
			#interrupt-cells = <0x01>;
			interrupt-map-mask = <0x00 0x00 0x00 0x07>;
			interrupt-map = <0x00 0x00 0x00 0x01 0x01 0x00 0x24 0x04 0x00 0x00 0x00 0x02 0x01 0x00 0x25 0x04 0x00 0x00 0x00 0x03 0x01 0x00 0x26 0x04 0x00 0x00 0x00 0x04 0x01 0x00 0x27 0x04>;
			clocks = <0x0c 0x2b 0x0c 0x2e 0x0c 0x2d>;
			clock-names = "core\0iface\0phy";
			resets = <0x0c 0x6c 0x0c 0x6b 0x0c 0x6a 0x0c 0x69 0x0c 0x68>;
			reset-names = "axi\0ahb\0por\0pci\0phy";
			status = "disabled";
			phandle = <0x91>;
		};
	};

	gpio-keys {
		compatible = "gpio-keys";
		input-name = "gpio-keys";
		pinctrl-names = "default";
		pinctrl-0 = <0x3a>;

		camera-focus {
			label = "camera_focus";
			gpios = <0x3b 0x03 0x01>;
			linux,input-type = <0x01>;
			linux,code = <0x210>;
		};

		camera-snapshot {
			label = "camera_snapshot";
			gpios = <0x3b 0x04 0x01>;
			linux,input-type = <0x01>;
			linux,code = <0xd4>;
		};

		volume-down {
			label = "volume_down";
			gpios = <0x3b 0x1d 0x01>;
			linux,input-type = <0x01>;
			linux,code = <0x72>;
		};

		volume-up {
			label = "volume_up";
			gpios = <0x3b 0x23 0x01>;
			linux,input-type = <0x01>;
			linux,code = <0x73>;
		};
	};

	__symbols__ {
		smem_region = "/reserved-memory/smem@80000000";
		L2 = "/cpus/l2-cache";
		CPU_SPC = "/cpus/idle-states/spc";
		cpu_alert0 = "/thermal-zones/cpu-thermal0/trips/trip0";
		cpu_crit0 = "/thermal-zones/cpu-thermal0/trips/trip1";
		cpu_alert1 = "/thermal-zones/cpu-thermal1/trips/trip0";
		cpu_crit1 = "/thermal-zones/cpu-thermal1/trips/trip1";
		cpu_alert2 = "/thermal-zones/cpu-thermal2/trips/trip0";
		cpu_crit2 = "/thermal-zones/cpu-thermal2/trips/trip1";
		cpu_alert3 = "/thermal-zones/cpu-thermal3/trips/trip0";
		cpu_crit3 = "/thermal-zones/cpu-thermal3/trips/trip1";
		sfpb_mutex = "/hwmutex";
		apps_smsm = "/smsm/apps@0";
		modem_smsm = "/smsm/modem@1";
		q6_smsm = "/smsm/q6@2";
		wcnss_smsm = "/smsm/wcnss@3";
		dsps_smsm = "/smsm/dsps@4";
		soc = "/soc";
		tlmm_pinmux = "/soc/pinctrl@800000";
		sdc4_gpios = "/soc/pinctrl@800000/sdc4-gpios";
		sdcc1_pins = "/soc/pinctrl@800000/sdcc1-pin-active";
		sdcc3_pins = "/soc/pinctrl@800000/sdcc3-pin-active";
		ps_hold = "/soc/pinctrl@800000/ps_hold";
		i2c1_pins = "/soc/pinctrl@800000/i2c1";
		i2c1_pins_sleep = "/soc/pinctrl@800000/i2c1_pins_sleep";
		gsbi1_uart_2pins = "/soc/pinctrl@800000/gsbi1_uart_2pins";
		gsbi1_uart_4pins = "/soc/pinctrl@800000/gsbi1_uart_4pins";
		i2c2_pins = "/soc/pinctrl@800000/i2c2";
		i2c2_pins_sleep = "/soc/pinctrl@800000/i2c2_pins_sleep";
		i2c3_pins = "/soc/pinctrl@800000/i2c3";
		i2c3_pins_sleep = "/soc/pinctrl@800000/i2c3_pins_sleep";
		i2c4_pins = "/soc/pinctrl@800000/i2c4";
		i2c4_pins_sleep = "/soc/pinctrl@800000/i2c4_pins_sleep";
		spi5_default = "/soc/pinctrl@800000/spi5_default";
		spi5_sleep = "/soc/pinctrl@800000/spi5_sleep";
		i2c6_pins = "/soc/pinctrl@800000/i2c6";
		i2c6_pins_sleep = "/soc/pinctrl@800000/i2c6_pins_sleep";
		gsbi6_uart_2pins = "/soc/pinctrl@800000/gsbi6_uart_2pins";
		gsbi6_uart_4pins = "/soc/pinctrl@800000/gsbi6_uart_4pins";
		gsbi7_uart_2pins = "/soc/pinctrl@800000/gsbi7_uart_2pins";
		gsbi7_uart_4pins = "/soc/pinctrl@800000/gsbi7_uart_4pins";
		i2c7_pins = "/soc/pinctrl@800000/i2c7";
		i2c7_pins_sleep = "/soc/pinctrl@800000/i2c7_pins_sleep";
		gsbi5_uart_pin_a = "/soc/pinctrl@800000/gsbi5-uart-pin-active";
		sdcc3_cd_pin_a = "/soc/pinctrl@800000/sdcc3-cd-pin-active";
		sfpb_wrapper_mutex = "/soc/syscon@1200000";
		intc = "/soc/interrupt-controller@2000000";
		acc0 = "/soc/clock-controller@2088000";
		acc1 = "/soc/clock-controller@2098000";
		acc2 = "/soc/clock-controller@20a8000";
		acc3 = "/soc/clock-controller@20b8000";
		saw0 = "/soc/power-controller@2089000";
		saw1 = "/soc/power-controller@2099000";
		saw2 = "/soc/power-controller@20a9000";
		saw3 = "/soc/power-controller@20b9000";
		sps_sic_non_secure = "/soc/sps-sic-non-secure@12100000";
		gsbi1 = "/soc/gsbi@12440000";
		gsbi1_serial = "/soc/gsbi@12440000/serial@12450000";
		gsbi1_i2c = "/soc/gsbi@12440000/i2c@12460000";
		gsbi2 = "/soc/gsbi@12480000";
		gsbi2_i2c = "/soc/gsbi@12480000/i2c@124a0000";
		gsbi3 = "/soc/gsbi@16200000";
		gsbi3_i2c = "/soc/gsbi@16200000/i2c@16280000";
		gsbi4 = "/soc/gsbi@16300000";
		gsbi4_i2c = "/soc/gsbi@16300000/i2c@16380000";
		gsbi5 = "/soc/gsbi@1a200000";
		gsbi5_serial = "/soc/gsbi@1a200000/serial@1a240000";
		gsbi5_spi = "/soc/gsbi@1a200000/spi@1a280000";
		gsbi6 = "/soc/gsbi@16500000";
		gsbi6_serial = "/soc/gsbi@16500000/serial@16540000";
		gsbi6_i2c = "/soc/gsbi@16500000/i2c@16580000";
		gsbi7 = "/soc/gsbi@16600000";
		gsbi7_serial = "/soc/gsbi@16600000/serial@16640000";
		gsbi7_i2c = "/soc/gsbi@16600000/i2c@16680000";
		pmicintc = "/soc/qcom,ssbi@500000/pmic@0";
		pm8921_gpio = "/soc/qcom,ssbi@500000/pmic@0/gpio@150";
		gpio_keys_pin_a = "/soc/qcom,ssbi@500000/pmic@0/gpio@150/gpio-keys-pin-active";
		pm8921_mpps = "/soc/qcom,ssbi@500000/pmic@0/mpps@50";
		qfprom = "/soc/qfprom@700000";
		tsens_calib = "/soc/qfprom@700000/calib";
		tsens_backup = "/soc/qfprom@700000/backup_calib";
		gcc = "/soc/clock-controller@900000";
		lcc = "/soc/clock-controller@28000000";
		mmcc = "/soc/clock-controller@4000000";
		l2cc = "/soc/clock-controller@2011000";
		rpmcc = "/soc/rpm@108000/clock-controller";
		pm8921_s1 = "/soc/rpm@108000/regulators/s1";
		pm8921_s2 = "/soc/rpm@108000/regulators/s2";
		pm8921_s3 = "/soc/rpm@108000/regulators/s3";
		pm8921_s4 = "/soc/rpm@108000/regulators/s4";
		pm8921_s7 = "/soc/rpm@108000/regulators/s7";
		pm8921_s8 = "/soc/rpm@108000/regulators/s8";
		pm8921_l1 = "/soc/rpm@108000/regulators/l1";
		pm8921_l2 = "/soc/rpm@108000/regulators/l2";
		pm8921_l3 = "/soc/rpm@108000/regulators/l3";
		pm8921_l4 = "/soc/rpm@108000/regulators/l4";
		pm8921_l5 = "/soc/rpm@108000/regulators/l5";
		pm8921_l6 = "/soc/rpm@108000/regulators/l6";
		pm8921_l7 = "/soc/rpm@108000/regulators/l7";
		pm8921_l8 = "/soc/rpm@108000/regulators/l8";
		pm8921_l9 = "/soc/rpm@108000/regulators/l9";
		pm8921_l10 = "/soc/rpm@108000/regulators/l10";
		pm8921_l11 = "/soc/rpm@108000/regulators/l11";
		pm8921_l12 = "/soc/rpm@108000/regulators/l12";
		pm8921_l14 = "/soc/rpm@108000/regulators/l14";
		pm8921_l15 = "/soc/rpm@108000/regulators/l15";
		pm8921_l16 = "/soc/rpm@108000/regulators/l16";
		pm8921_l17 = "/soc/rpm@108000/regulators/l17";
		pm8921_l18 = "/soc/rpm@108000/regulators/l18";
		pm8921_l21 = "/soc/rpm@108000/regulators/l21";
		pm8921_l22 = "/soc/rpm@108000/regulators/l22";
		pm8921_l23 = "/soc/rpm@108000/regulators/l23";
		pm8921_l24 = "/soc/rpm@108000/regulators/l24";
		pm8921_l25 = "/soc/rpm@108000/regulators/l25";
		pm8921_l26 = "/soc/rpm@108000/regulators/l26";
		pm8921_l27 = "/soc/rpm@108000/regulators/l27";
		pm8921_l28 = "/soc/rpm@108000/regulators/l28";
		pm8921_l29 = "/soc/rpm@108000/regulators/l29";
		pm8921_lvs1 = "/soc/rpm@108000/regulators/lvs1";
		pm8921_lvs2 = "/soc/rpm@108000/regulators/lvs2";
		pm8921_lvs3 = "/soc/rpm@108000/regulators/lvs3";
		pm8921_lvs4 = "/soc/rpm@108000/regulators/lvs4";
		pm8921_lvs5 = "/soc/rpm@108000/regulators/lvs5";
		pm8921_lvs6 = "/soc/rpm@108000/regulators/lvs6";
		pm8921_lvs7 = "/soc/rpm@108000/regulators/lvs7";
		pm8921_usb_switch = "/soc/rpm@108000/regulators/usb-switch";
		pm8921_hdmi_switch = "/soc/rpm@108000/regulators/hdmi-switch";
		pm8921_ncp = "/soc/rpm@108000/regulators/ncp";
		usb1_phy = "/soc/phy@12500000";
		usb3_phy = "/soc/phy@12520000";
		usb4_phy = "/soc/phy@12530000";
		gadget1 = "/soc/gadget@12500000";
		usb1 = "/soc/usb@12500000";
		usb3 = "/soc/usb@12520000";
		usb4 = "/soc/usb@12530000";
		sata_phy0 = "/soc/phy@1b400000";
		sata0 = "/soc/sata@29000000";
		sdcc1bam = "/soc/dma@12402000";
		sdcc3bam = "/soc/dma@12182000";
		sdcc4bam = "/soc/dma@121c2000";
		sdcc1 = "/soc/amba/sdcc@12400000";
		sdcc3 = "/soc/amba/sdcc@12180000";
		sdcc4 = "/soc/amba/sdcc@121c0000";
		tcsr = "/soc/syscon@1a400000";
		pcie = "/soc/pci@1b500000";
	};
};
